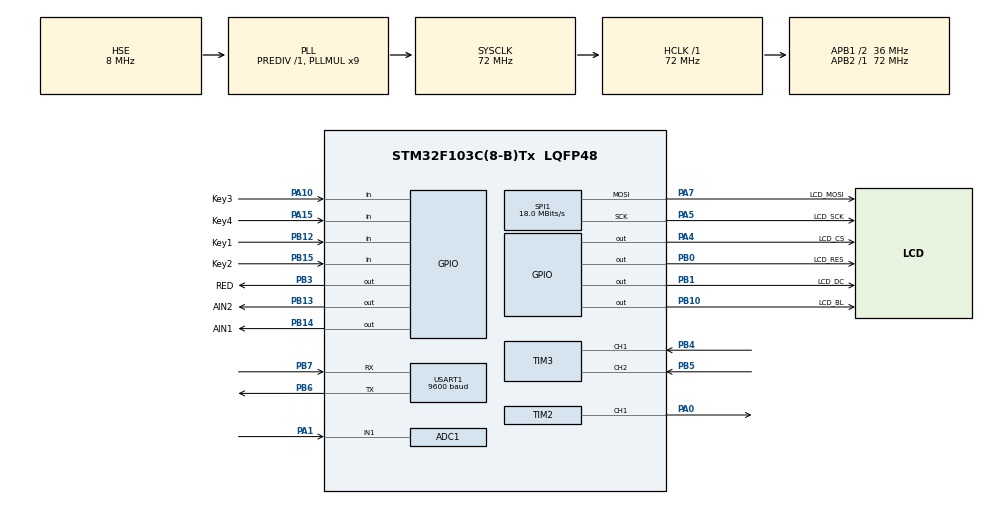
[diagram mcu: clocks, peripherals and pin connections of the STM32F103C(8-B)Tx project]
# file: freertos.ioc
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ADC1.Channel-1\#ChannelRegularConversion=ADC_CHANNEL_1
ADC1.ContinuousConvMode=ENABLE
ADC1.NbrOfConversionFlag=1
ADC1.Rank-1\#ChannelRegularConversion=1
ADC1.SamplingTime-1\#ChannelRegularConversion=ADC_SAMPLETIME_1CYCLE_5
ADC1.master=1
Dma.ADC1.0.Direction=DMA_PERIPH_TO_MEMORY
Dma.ADC1.0.Instance=DMA1_Channel1
Dma.ADC1.0.MemDataAlignment=DMA_MDATAALIGN_HALFWORD
Dma.ADC1.0.MemInc=DMA_MINC_ENABLE
Dma.ADC1.0.Mode=DMA_CIRCULAR
Dma.ADC1.0.PeriphDataAlignment=DMA_PDATAALIGN_HALFWORD
Dma.ADC1.0.PeriphInc=DMA_PINC_DISABLE
Dma.ADC1.0.Priority=DMA_PRIORITY_LOW
Dma.Request0=ADC1
FREERTOS.Tasks01=defaultTask,24,128,StartDefaultTask,Default,NULL,Dynamic,NULL,NULL
Mcu.Family=STM32F1
Mcu.Name=STM32F103C(8-B)Tx
Mcu.Package=LQFP48
NVIC.PriorityGroup=NVIC_PRIORITYGROUP_4
NVIC.TIM1_UP_IRQn=true\:5\:0\:false\:false\:true\:true\:true\:true\:true
NVIC.TIM4_IRQn=true\:15\:0\:false\:false\:true\:false\:false\:true\:true
NVIC.TimeBase=TIM4_IRQn
NVIC.TimeBaseIP=TIM4
PA0-WKUP.Signal=S_TIM2_CH1_ETR
PA1.Signal=ADCx_IN1
PA10.GPIO_Label=Key3
PA10.GPIO_PuPd=GPIO_PULLDOWN
PA10.Signal=GPIO_Input
PA13.Mode=Serial_Wire
PA13.Signal=SYS_JTMS-SWDIO
PA14.Mode=Serial_Wire
PA14.Signal=SYS_JTCK-SWCLK
PA15.GPIO_Label=Key4
PA15.GPIO_PuPd=GPIO_PULLDOWN
PA15.Signal=GPIO_Input
PA4.GPIO_Label=LCD_CS
PA4.GPIO_PuPd=GPIO_PULLUP
PA4.GPIO_Speed=GPIO_SPEED_FREQ_LOW
PA4.PinState=GPIO_PIN_SET
PA4.Signal=GPIO_Output
PA5.GPIO_Label=LCD_SCK
PA5.Mode=TX_Only_Simplex_Unidirect_Master
PA5.Signal=SPI1_SCK
PA7.GPIO_Label=LCD_MOSI
PA7.Mode=TX_Only_Simplex_Unidirect_Master
PA7.Signal=SPI1_MOSI
PB0.GPIO_Label=LCD_RES
PB0.GPIO_PuPd=GPIO_PULLUP
PB0.PinState=GPIO_PIN_SET
PB0.Signal=GPIO_Output
PB1.GPIO_Label=LCD_DC
PB1.GPIO_PuPd=GPIO_PULLUP
PB1.GPIO_Speed=GPIO_SPEED_FREQ_LOW
PB1.PinState=GPIO_PIN_SET
PB1.Signal=GPIO_Output
PB10.GPIO_Label=LCD_BL
PB10.GPIO_PuPd=GPIO_NOPULL
PB10.GPIO_Speed=GPIO_SPEED_FREQ_HIGH
PB10.PinState=GPIO_PIN_SET
PB10.Signal=GPIO_Output
PB12.GPIO_Label=Key1
PB12.GPIO_PuPd=GPIO_PULLDOWN
PB12.Signal=GPIO_Input
PB13.GPIO_Label=AIN2
PB13.Signal=GPIO_Output
PB14.GPIO_Label=AIN1
PB14.Signal=GPIO_Output
PB15.GPIO_Label=Key2
PB15.GPIO_PuPd=GPIO_PULLDOWN
PB15.Signal=GPIO_Input
PB3.GPIO_Label=RED
PB3.GPIO_PuPd=GPIO_PULLUP
PB3.GPIO_Speed=GPIO_SPEED_FREQ_HIGH
PB3.Signal=GPIO_Output
PB4.GPIO_Mode=GPIO_MODE_INPUT
PB4.GPIO_PuPd=GPIO_PULLUP
PB4.Signal=S_TIM3_CH1
PB5.GPIO_PuPd=GPIO_PULLUP
PB5.Signal=S_TIM3_CH2
PB6.Mode=Asynchronous
PB6.Signal=USART1_TX
PB7.Mode=Asynchronous
PB7.Signal=USART1_RX
PD0-OSC_IN.Mode=HSE-External-Oscillator
PD0-OSC_IN.Signal=RCC_OSC_IN
PD1-OSC_OUT.Mode=HSE-External-Oscillator
PD1-OSC_OUT.Signal=RCC_OSC_OUT
ProjectManager.HeapSize=0x200
ProjectManager.StackSize=0x400
ProjectManager.TargetToolchain=MDK-ARM V5.32
RCC.ADCPresc=RCC_ADCPCLK2_DIV6
RCC.AHBFreq_Value=72000000
RCC.APB1CLKDivider=RCC_HCLK_DIV2
RCC.APB1Freq_Value=36000000
RCC.APB1TimFreq_Value=72000000
RCC.APB2Freq_Value=72000000
RCC.APB2TimFreq_Value=72000000
RCC.HCLKFreq_Value=72000000
RCC.PLLMUL=RCC_PLL_MUL9
RCC.PLLSourceVirtual=RCC_PLLSOURCE_HSE
RCC.RTCClockSelection=RCC_RTCCLKSOURCE_LSE
RCC.SYSCLKFreq_VALUE=72000000
RCC.SYSCLKSource=RCC_SYSCLKSOURCE_PLLCLK
RCC.USBFreq_Value=72000000
SH.ADCx_IN1.0=ADC1_IN1,IN1
SH.S_TIM2_CH1_ETR.0=TIM2_CH1,PWM Generation1 CH1
SH.S_TIM3_CH1.0=TIM3_CH1,Encoder_Interface
SH.S_TIM3_CH2.0=TIM3_CH2,Encoder_Interface
SPI1.BaudRatePrescaler=SPI_BAUDRATEPRESCALER_4
SPI1.CalculateBaudRate=18.0 MBits/s
SPI1.Direction=SPI_DIRECTION_2LINES
SPI1.Mode=SPI_MODE_MASTER
SPI1.VirtualType=VM_MASTER
TIM1.Period=100 - 1
TIM1.Prescaler=720 - 1
TIM2.Channel-PWM\ Generation1\ CH1=TIM_CHANNEL_1
TIM2.Period=100 - 1
TIM2.Prescaler=36 - 1
TIM3.EncoderMode=TIM_ENCODERMODE_TI12
TIM3.IC1Filter=15
TIM3.IC1Polarity=TIM_ICPOLARITY_FALLING
TIM3.IC2Filter=15
USART1.BaudRate=9600
USART1.VirtualMode=VM_ASYNC
VP_FREERTOS_VS_CMSIS_V2.Mode=CMSIS_V2
VP_SYS_VS_tim4.Mode=TIM4
VP_TIM1_VS_ClockSourceINT.Mode=Internal
VP_TIM2_VS_ClockSourceINT.Mode=Internal
board=custom

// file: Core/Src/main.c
/* USER CODE BEGIN Header */
/**
 ******************************************************************************
 * @file           : main.c
 * @brief          : Main program body
 ******************************************************************************
 * @attention
 *
 * Copyright (c) 2026 STMicroelectronics.
 * All rights reserved.
 *
 * This software is licensed under terms that can be found in the LICENSE file
 * in the root directory of this software component.
 * If no LICENSE file comes with this software, it is provided AS-IS.
 *
 ******************************************************************************
 */
/* USER CODE END Header */
#include "main.h"
#include "cmsis_os.h"
#include "adc.h"
#include "dma.h"
#include "spi.h"
#include "tim.h"
#include "usart.h"
#include "gpio.h"

/* USER CODE BEGIN Includes */
#include "ALL.h"
/* USER CODE END Includes */

void SystemClock_Config(void);
void MX_FREERTOS_Init(void);

/* USER CODE BEGIN 0 */

uint8_t flag;
// int num1, num2;
/* USER CODE END 0 */

int main(void)
{

  /* MCU Configuration--------------------------------------------------------*/

  /* Reset of all peripherals, Initializes the Flash interface and the Systick. */
  HAL_Init();

  /* Configure the system clock */
  SystemClock_Config();

  /* Initialize all configured peripherals */
  MX_GPIO_Init();
  MX_DMA_Init();
  MX_SPI1_Init();
  MX_TIM1_Init();
  MX_ADC1_Init();
  MX_USART1_UART_Init();
  MX_TIM2_Init();
  MX_TIM3_Init();
  /* USER CODE BEGIN 2 */

  Key_Init();

  /* USER CODE END 2 */

  /* Init scheduler */
  osKernelInitialize();  /* Call init function for freertos objects (in cmsis_os2.c) */
  MX_FREERTOS_Init();

  /* Start scheduler */
  osKernelStart();

  /* We should never get here as control is now taken by the scheduler */

  /* Infinite loop */
  while (1)
  {

  }
}

void SystemClock_Config(void)
{
  RCC_OscInitTypeDef RCC_OscInitStruct = {0};
  RCC_ClkInitTypeDef RCC_ClkInitStruct = {0};
  RCC_PeriphCLKInitTypeDef PeriphClkInit = {0};

  /** Initializes the RCC Oscillators according to the specified parameters
  * in the RCC_OscInitTypeDef structure.
  */
  RCC_OscInitStruct.OscillatorType = RCC_OSCILLATORTYPE_HSE;
  RCC_OscInitStruct.HSEState = RCC_HSE_ON;
  RCC_OscInitStruct.HSEPredivValue = RCC_HSE_PREDIV_DIV1;
  RCC_OscInitStruct.HSIState = RCC_HSI_ON;
  RCC_OscInitStruct.PLL.PLLState = RCC_PLL_ON;
  RCC_OscInitStruct.PLL.PLLSource = RCC_PLLSOURCE_HSE;
  RCC_OscInitStruct.PLL.PLLMUL = RCC_PLL_MUL9;
  if (HAL_RCC_OscConfig(&RCC_OscInitStruct) != HAL_OK)
  {
    Error_Handler();
  }

  /** Initializes the CPU, AHB and APB buses clocks
  */
  RCC_ClkInitStruct.ClockType = RCC_CLOCKTYPE_HCLK|RCC_CLOCKTYPE_SYSCLK
                              |RCC_CLOCKTYPE_PCLK1|RCC_CLOCKTYPE_PCLK2;
  RCC_ClkInitStruct.SYSCLKSource = RCC_SYSCLKSOURCE_PLLCLK;
  RCC_ClkInitStruct.AHBCLKDivider = RCC_SYSCLK_DIV1;
  RCC_ClkInitStruct.APB1CLKDivider = RCC_HCLK_DIV2;
  RCC_ClkInitStruct.APB2CLKDivider = RCC_HCLK_DIV1;

  if (HAL_RCC_ClockConfig(&RCC_ClkInitStruct, FLASH_LATENCY_2) != HAL_OK)
  {
    Error_Handler();
  }
  PeriphClkInit.PeriphClockSelection = RCC_PERIPHCLK_ADC;
  PeriphClkInit.AdcClockSelection = RCC_ADCPCLK2_DIV6;
  if (HAL_RCCEx_PeriphCLKConfig(&PeriphClkInit) != HAL_OK)
  {
    Error_Handler();
  }
}

void HAL_TIM_PeriodElapsedCallback(TIM_HandleTypeDef *htim)
{
  if (htim->Instance == TIM4)
  {
    HAL_IncTick();
  }
}

void Error_Handler(void)
{
  __disable_irq();
  while (1)
  {
  }
}
